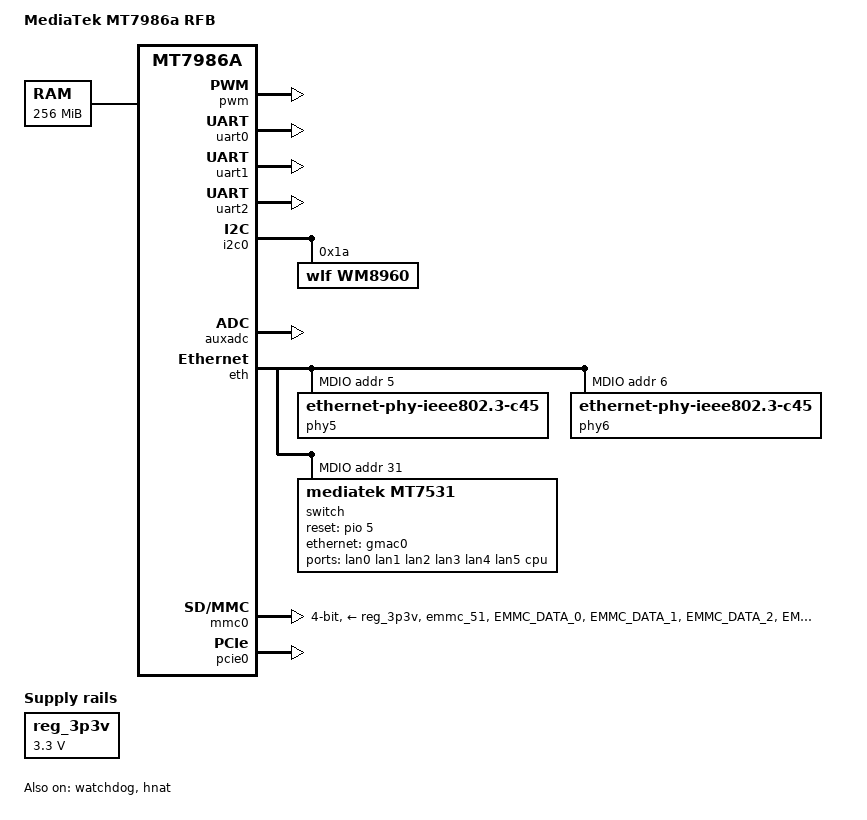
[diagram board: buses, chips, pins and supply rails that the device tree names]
/dts-v1/;
#include "mt7986a.dtsi"
#include "mt7986a-pinctrl.dtsi"
/ {
	model = "MediaTek MT7986a RFB";
	compatible = "mediatek,mt7986a-2500wan-sd-rfb";
	chosen {
		bootargs = "console=ttyS0,115200n1 loglevel=8  \
			earlycon=uart8250,mmio32,0x11002000 \
			root=PARTLABEL=rootfs rootwait rootfstype=squashfs,f2fs";
	};

	memory {
		reg = <0 0x40000000 0 0x10000000>;
	};

	sound {
		compatible = "mediatek,mt7986-wm8960-machine";
		mediatek,platform = <&afe>;
		audio-routing = "Headphone", "HP_L",
				"Headphone", "HP_R",
				"LINPUT1", "AMIC",
				"RINPUT1", "AMIC";
		mediatek,audio-codec = <&wm8960>;
		status = "okay";
	};

	reg_3p3v: regulator-3p3v {
		compatible = "regulator-fixed";
		regulator-name = "fixed-3.3V";
		regulator-min-microvolt = <3300000>;
		regulator-max-microvolt = <3300000>;
		regulator-boot-on;
		regulator-always-on;
	};
};

&fan {
	pwms = <&pwm 1 50000 0>;
	status = "disabled";
};

&pwm {
	pinctrl-names = "default";
	pinctrl-0 = <&pwm0_pin &pwm1_pin_g1>;
	status = "okay";
};

&uart0 {
	status = "okay";
};

&uart1 {
	pinctrl-names = "default";
	pinctrl-0 = <&uart1_pins>;
	status = "okay";
};

&uart2 {
	pinctrl-names = "default";
	pinctrl-0 = <&uart2_pins>;
	status = "okay";
};

&i2c0 {
	pinctrl-names = "default";
	pinctrl-0 = <&i2c_pins>;
	status = "okay";

	wm8960: wm8960@1a {
		compatible = "wlf,wm8960";
		reg = <0x1a>;
	};
};

&auxadc {
	status = "okay";
};

&watchdog {
	status = "okay";
};

&eth {
	status = "okay";

	gmac0: mac@0 {
		compatible = "mediatek,eth-mac";
		reg = <0>;
		phy-mode = "2500base-x";

		fixed-link {
			speed = <2500>;
			full-duplex;
			pause;
		};
	};

	gmac1: mac@1 {
		compatible = "mediatek,eth-mac";
		reg = <1>;
		phy-mode = "2500base-x";
		phy-handle = <&phy6>;
	};

	mdio: mdio-bus {
		#address-cells = <1>;
		#size-cells = <0>;

		reset-gpios = <&pio 6 1>;
		reset-delay-us = <600>;

		phy5: phy@5 {
			compatible = "ethernet-phy-ieee802.3-c45";
			reg = <5>;
		};

		phy6: phy@6 {
			compatible = "ethernet-phy-ieee802.3-c45";
			reg = <6>;
		};

		switch@0 {
			compatible = "mediatek,mt7531";
			reg = <31>;
			reset-gpios = <&pio 5 0>;

			ports {
				#address-cells = <1>;
				#size-cells = <0>;

				port@0 {
					reg = <0>;
					label = "lan0";
				};

				port@1 {
					reg = <1>;
					label = "lan1";
				};

				port@2 {
					reg = <2>;
					label = "lan2";
				};

				port@3 {
					reg = <3>;
					label = "lan3";
				};

				port@4 {
					reg = <4>;
					label = "lan4";
				};

				port@5 {
					reg = <5>;
					label = "lan5";
					phy-mode = "2500base-x";
					phy-handle = <&phy5>;
				};

				port@6 {
					reg = <6>;
					label = "cpu";
					ethernet = <&gmac0>;
					phy-mode = "2500base-x";

					fixed-link {
						speed = <2500>;
						full-duplex;
						pause;
					};
				};
			};
		};
	};
};

&hnat {
	mtketh-wan = "eth1";
	mtketh-lan = "lan";
	mtketh-max-gmac = <2>;
	status = "okay";
};

&mmc0 {
	pinctrl-names = "default", "state_uhs";
	pinctrl-0 = <&mmc0_pins_default>;
	pinctrl-1 = <&mmc0_pins_uhs>;
	bus-width = <4>;
	max-frequency = <52000000>;
	cap-sd-highspeed;
	vmmc-supply = <&reg_3p3v>;
	vqmmc-supply = <&reg_3p3v>;
	status = "okay";
};

&pcie0 {
	pinctrl-names = "default";
	pinctrl-0 = <&pcie0_pins>;
	status = "okay";
};

&pio {
	mmc0_pins_default: mmc0-pins-50-to-61-default {
		mux {
			function = "flash";
			groups = "emmc_51";
		};
		conf-cmd-dat {
			pins = "EMMC_DATA_0", "EMMC_DATA_1", "EMMC_DATA_2",
			       "EMMC_DATA_3", "EMMC_DATA_4", "EMMC_DATA_5",
			       "EMMC_DATA_6", "EMMC_DATA_7", "EMMC_CMD";
			input-enable;
			drive-strength = <MTK_DRIVE_4mA>;
			mediatek,pull-up-adv = <1>;	/* pull-up 10K */
		};
		conf-clk {
			pins = "EMMC_CK";
			drive-strength = <MTK_DRIVE_6mA>;
			mediatek,pull-down-adv = <2>;	/* pull-down 50K */
		};
		conf-ds {
			pins = "EMMC_DSL";
			mediatek,pull-down-adv = <2>;	/* pull-down 50K */
		};
		conf-rst {
			pins = "EMMC_RSTB";
			drive-strength = <MTK_DRIVE_4mA>;
			mediatek,pull-up-adv = <1>;	/* pull-up 10K */
		};
	};

	mmc0_pins_uhs: mmc0-pins-50-to-61-uhs {
		mux {
			function = "flash";
			groups = "emmc_51";
		};
		conf-cmd-dat {
			pins = "EMMC_DATA_0", "EMMC_DATA_1", "EMMC_DATA_2",
			       "EMMC_DATA_3", "EMMC_DATA_4", "EMMC_DATA_5",
			       "EMMC_DATA_6", "EMMC_DATA_7", "EMMC_CMD";
			input-enable;
			drive-strength = <MTK_DRIVE_4mA>;
			mediatek,pull-up-adv = <1>;	/* pull-up 10K */
		};
		conf-clk {
			pins = "EMMC_CK";
			drive-strength = <MTK_DRIVE_6mA>;
			mediatek,pull-down-adv = <2>;	/* pull-down 50K */
		};
		conf-ds {
			pins = "EMMC_DSL";
			mediatek,pull-down-adv = <2>;	/* pull-down 50K */
		};
		conf-rst {
			pins = "EMMC_RSTB";
			drive-strength = <MTK_DRIVE_4mA>;
			mediatek,pull-up-adv = <1>;	/* pull-up 10K */
		};
	};

	wf_2g_5g_pins: wf_2g_5g-pins {
		mux {
			function = "wifi";
			groups = "wf_2g", "wf_5g";
		};
		conf {
			pins = "WF0_HB1", "WF0_HB2", "WF0_HB3", "WF0_HB4",
			       "WF0_HB0", "WF0_HB0_B", "WF0_HB5", "WF0_HB6",
			       "WF0_HB7", "WF0_HB8", "WF0_HB9", "WF0_HB10",
			       "WF0_TOP_CLK", "WF0_TOP_DATA", "WF1_HB1",
			       "WF1_HB2", "WF1_HB3", "WF1_HB4", "WF1_HB0",
			       "WF1_HB5", "WF1_HB6", "WF1_HB7", "WF1_HB8",
			       "WF1_TOP_CLK", "WF1_TOP_DATA";
			drive-strength = <MTK_DRIVE_4mA>;
		};
	};

	wf_dbdc_pins: wf_dbdc-pins {
		mux {
			function = "wifi";
			groups = "wf_dbdc";
		};
		conf {
			pins = "WF0_HB1", "WF0_HB2", "WF0_HB3", "WF0_HB4",
			       "WF0_HB0", "WF0_HB0_B", "WF0_HB5", "WF0_HB6",
			       "WF0_HB7", "WF0_HB8", "WF0_HB9", "WF0_HB10",
			       "WF0_TOP_CLK", "WF0_TOP_DATA", "WF1_HB1",
			       "WF1_HB2", "WF1_HB3", "WF1_HB4", "WF1_HB0",
			       "WF1_HB5", "WF1_HB6", "WF1_HB7", "WF1_HB8",
			       "WF1_TOP_CLK", "WF1_TOP_DATA";
			drive-strength = <MTK_DRIVE_4mA>;
		};
	};
};
